# FM33A0XXEV register map
File version: 1.0
CPU: SC000, little endian, no MPU, no FPU, 3 interrupt priority bits
Registers are 32-bit, read-write, reset 0x0 unless marked. A register's access mark holds for its fields unless they carry their own. Offsets are from the block's base; [hi:lo] are bit positions.

## CRC — CRC module information
Base 0x40010000
0x00 DR — CRC Data Register
  [31:0] DR — DR field description
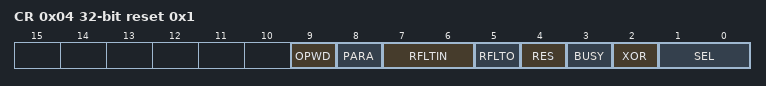
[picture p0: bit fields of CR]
0x04 CR reset 0x1 — CRC Control Register
  [9] OPWD — OPWD field description
  [8] PARA — PARA field description
  [7:6] RFLTIN — RFLTIN field description
  [5] RFLTO — RFLTO field description
  [4] RES ro — RES field description
  [3] BUSY ro — BUSY field description
  [2] XOR — XOR field description
  [1:0] SEL — SEL field description
0x08 LFSR — CRC Linear Feedback Shift Register
  [31:0] LFSR — LFSR field description
0x0C XOR — CRC output XOR Register
  [31:0] XOR — XOR field description
0x1C POLY — CRC Polynominal Register
  [31:0] POLY — POLY field description

## BT1 — BT1 module information
Base 0x40013000
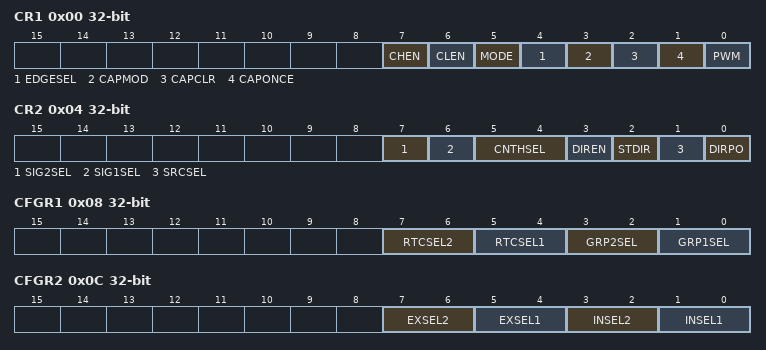
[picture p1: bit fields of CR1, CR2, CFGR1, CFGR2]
0x00 CR1 — Basic Timer 1 Control Register 1
  [7] CHEN — CHEN field description
  [6] CLEN — CLEN field description
  [5] MODE — MODE field description
  [4] EDGESEL — EDGESEL field description
  [3] CAPMOD — CAPMOD field description
  [2] CAPCLR — CAPCLR field description
  [1] CAPONCE — CAPONCE field description
  [0] PWM — PWM field description
0x04 CR2 — Basic Timer 1 Control Register 2
  [7] SIG2SEL — SIG2SEL field description
  [6] SIG1SEL — SIG1SEL field description
  [5:4] CNTHSEL — CNTHSEL field description
  [3] DIREN — DIREN field description
  [2] STDIR — STDIR field description
  [1] SRCSEL — SRCSEL field description
  [0] DIRPO — DIRPO field description
0x08 CFGR1 — Basic Timer 1 Config Register 1
  [7:6] RTCSEL2 — RTCSEL2 field description
  [5:4] RTCSEL1 — RTCSEL1 field description
  [3:2] GRP2SEL — GRP2SEL field description
  [1:0] GRP1SEL — GRP1SEL field description
0x0C CFGR2 — Basic Timer 1 Config Register 2
  [7:6] EXSEL2 — EXSEL2 field description
  [5:4] EXSEL1 — EXSEL1 field description
  [3:2] INSEL2 — INSEL2 field description
  [1:0] INSEL1 — INSEL1 field description
0x10 PRES — Basic Timer 1 Prescaler Register
  [7:0] PRESCALE — PRESCALE field description
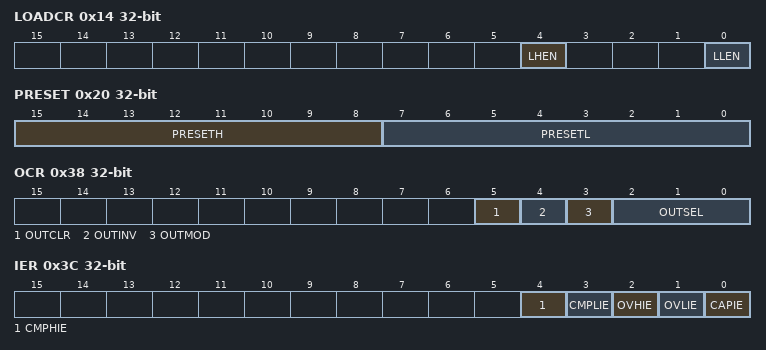
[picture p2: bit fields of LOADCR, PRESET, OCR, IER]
0x14 LOADCR — Basic Timer 1 Load Control Register
  [4] LHEN — LHEN field description
  [0] LLEN — LLEN field description
0x18 CNTL — Basic Timer 1 Counter Low
  [7:0] CNTL ro — CNTL field description
0x1C CNTH — Basic Timer 1 Counter High
  [7:0] CNTH ro — CNTH field description
0x20 PRESET — Basic Timer 1 Preset Register
  [15:8] PRESETH — PRESETH field description
  [7:0] PRESETL — PRESETL field description
0x24 LOADL — Basic Timer 1 Load Register Low
  [7:0] LOADL — LOADL field description
0x28 LOADH — Basic Timer 1 Load Register High
  [7:0] LOADH — LOADH field description
0x2C CMPL — Basic Timer 1 Compare Register Low
  [7:0] CMPL — CMPL field description
0x30 CMPH — Basic Timer 1 Compare Register High
  [7:0] CMPH — CMPH field description
0x34 OUTCNT — Basic Timer 1 Output Counter
  [11:0] OUTCNT — OUTCNT field description
0x38 OCR — Basic Timer 1 Output Control Register
  [5] OUTCLR — OUTCLR field description
  [4] OUTINV — OUTINV field description
  [3] OUTMOD — OUTMOD field description
  [2:0] OUTSEL — OUTSEL field description
0x3C IER — Basic Timer 1 Interrupt Enable Register
  [4] CMPHIE — CMPHIE field description
  [3] CMPLIE — CMPLIE field description
  [2] OVHIE — OVHIE field description
  [1] OVLIE — OVLIE field description
  [0] CAPIE — CAPIE field description
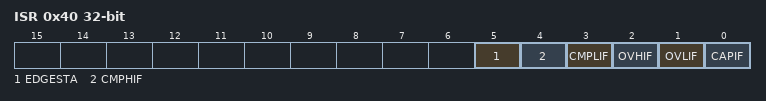
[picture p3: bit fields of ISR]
0x40 ISR — Basic Timer 1 Interrupt Status Register
  [5] EDGESTA ro — EDGESTA field description
  [4] CMPHIF — CMPHIF field description
  [3] CMPLIF — CMPLIF field description
  [2] OVHIF — OVHIF field description
  [1] OVLIF — OVLIF field description
  [0] CAPIF — CAPIF field description

## BT2 — BT2 module information
Base 0x40013044
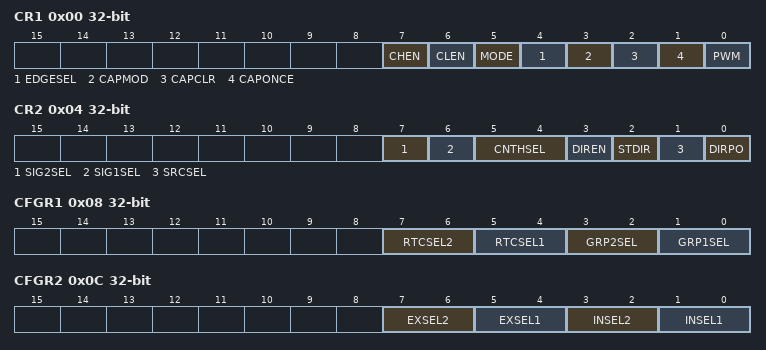
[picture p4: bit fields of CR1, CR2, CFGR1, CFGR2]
0x00 CR1 — Basic Timer2 Control Register 1
  [7] CHEN — CHEN field description
  [6] CLEN — CLEN field description
  [5] MODE — MODE field description
  [4] EDGESEL — EDGESEL field description
  [3] CAPMOD — CAPMOD field description
  [2] CAPCLR — CAPCLR field description
  [1] CAPONCE — CAPONCE field description
  [0] PWM — PWM field description
0x04 CR2 — Basic Timer2 Control Register 2
  [7] SIG2SEL — SIG2SEL field description
  [6] SIG1SEL — SIG1SEL field description
  [5:4] CNTHSEL — CNTHSEL field description
  [3] DIREN — DIREN field description
  [2] STDIR — STDIR field description
  [1] SRCSEL — SRCSEL field description
  [0] DIRPO — DIRPO field description
0x08 CFGR1 — Basic Timer2 Config Register 1
  [7:6] RTCSEL2 — RTCSEL2 field description
  [5:4] RTCSEL1 — RTCSEL1 field description
  [3:2] GRP2SEL — GRP2SEL field description
  [1:0] GRP1SEL — GRP1SEL field description
0x0C CFGR2 — Basic Timer2 Config Register 2
  [7:6] EXSEL2 — EXSEL2 field description
  [5:4] EXSEL1 — EXSEL1 field description
  [3:2] INSEL2 — INSEL2 field description
  [1:0] INSEL1 — INSEL1 field description
0x10 PRES — Basic Timer2 Prescaler Register
  [7:0] PRESCALE — PRESCALE field description
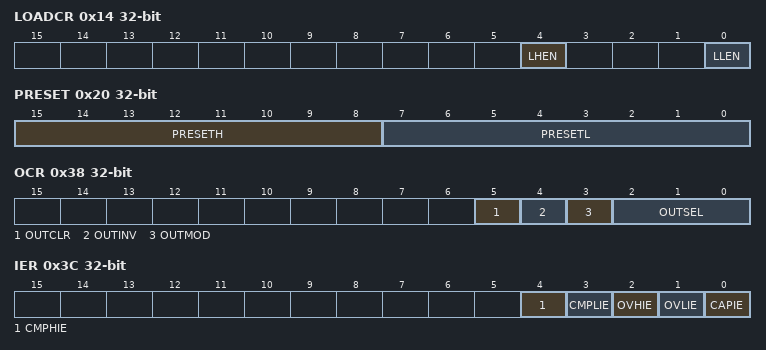
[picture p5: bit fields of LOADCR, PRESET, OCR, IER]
0x14 LOADCR — Basic Timer2 Load Control Register
  [4] LHEN — LHEN field description
  [0] LLEN — LLEN field description
0x18 CNTL — Basic Timer2 Counter Low
  [7:0] CNTL ro — CNTL field description
0x1C CNTH — Basic Timer2 Counter High
  [7:0] CNTH ro — CNTH field description
0x20 PRESET — Basic Timer2 Preset Register
  [15:8] PRESETH — PRESETH field description
  [7:0] PRESETL — PRESETL field description
0x24 LOADL — Basic Timer2 Load Register Low
  [7:0] LOADL — LOADL field description
0x28 LOADH — Basic Timer2 Load Register High
  [7:0] LOADH — LOADH field description
0x2C CMPL — Basic Timer2 Compare Register Low
  [7:0] CMPL — CMPL field description
0x30 CMPH — Basic Timer2 Compare Register High
  [7:0] CMPH — CMPH field description
0x34 OUTCNT — Basic Timer2 Output Counter
  [11:0] OUTCNT — OUTCNT field description
0x38 OCR — Basic Timer2 Output Control Register
  [5] OUTCLR — OUTCLR field description
  [4] OUTINV — OUTINV field description
  [3] OUTMOD — OUTMOD field description
  [2:0] OUTSEL — OUTSEL field description
0x3C IER — Basic Timer2 Interrupt Enable Register
  [4] CMPHIE — CMPHIE field description
  [3] CMPLIE — CMPLIE field description
  [2] OVHIE — OVHIE field description
  [1] OVLIE — OVLIE field description
  [0] CAPIE — CAPIE field description
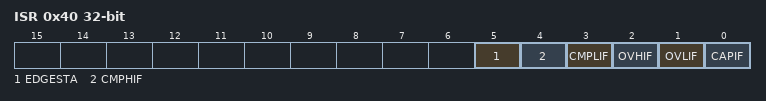
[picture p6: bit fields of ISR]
0x40 ISR — Basic Timer2 Interrupt Status Register
  [5] EDGESTA ro — EDGESTA field description
  [4] CMPHIF — CMPHIF field description
  [3] CMPLIF — CMPLIF field description
  [2] OVHIF — OVHIF field description
  [1] OVLIF — OVLIF field description
  [0] CAPIF — CAPIF field description
